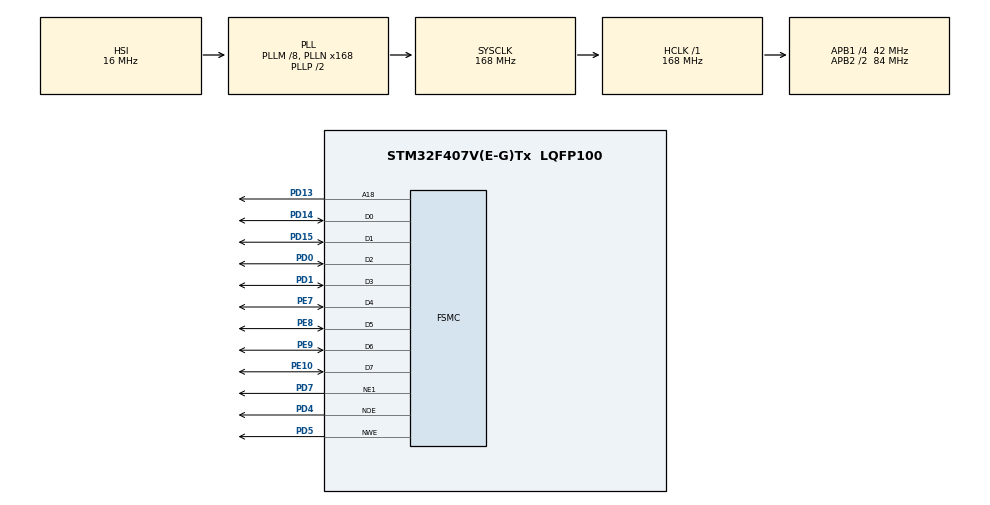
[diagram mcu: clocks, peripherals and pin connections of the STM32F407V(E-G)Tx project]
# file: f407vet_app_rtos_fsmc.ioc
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FREERTOS.Mutexes01=myLcdDma,Dynamic,NULL
FREERTOS.Tasks01=defaultTask,0,256,StartDefaultTask,As weak,NULL,Dynamic,NULL,NULL;myLopriority,-3,128,StartLopriority,As weak,NULL,Dynamic,NULL,NULL
FREERTOS.Timers01=myTimer01,cbTimer,osTimerPeriodic,As weak,NULL,Dynamic,NULL
FREERTOS.configUSE_TIMERS=1
FSMC.AddressSetupTime1=8
FSMC.BusTurnAroundDuration1=8
FSMC.DataSetupTime1=10
FSMC.ExtendedMode1=FSMC_EXTENDED_MODE_DISABLE
Mcu.Family=STM32F4
Mcu.Name=STM32F407V(E-G)Tx
Mcu.Package=LQFP100
NVIC.PriorityGroup=NVIC_PRIORITYGROUP_4
NVIC.TIM6_DAC_IRQn=true\:0\:0\:false\:false\:true\:false\:false
NVIC.TimeBase=TIM6_DAC_IRQn
NVIC.TimeBaseIP=TIM6
PA13.Mode=Trace_Asynchronous_SW
PA13.Signal=SYS_JTMS-SWDIO
PA14.Mode=Trace_Asynchronous_SW
PA14.Signal=SYS_JTCK-SWCLK
PB3.Mode=Trace_Asynchronous_SW
PB3.Signal=SYS_JTDO-SWO
PC14-OSC32_IN.Mode=LSE-External-Oscillator
PC14-OSC32_IN.Signal=RCC_OSC32_IN
PC15-OSC32_OUT.Mode=LSE-External-Oscillator
PC15-OSC32_OUT.Signal=RCC_OSC32_OUT
PD0.Mode=8b-d1
PD0.Signal=FSMC_D2
PD1.Mode=8b-d1
PD1.Signal=FSMC_D3
PD13.Mode=A18_1
PD13.Signal=FSMC_A18
PD14.Mode=8b-d1
PD14.Signal=FSMC_D0
PD15.Mode=8b-d1
PD15.Signal=FSMC_D1
PD4.Mode=Lcd1
PD4.Signal=FSMC_NOE
PD5.Mode=Lcd1
PD5.Signal=FSMC_NWE
PD7.Mode=NorPsramChipSelect1_1
PD7.Signal=FSMC_NE1
PE10.Mode=8b-d1
PE10.Signal=FSMC_D7
PE7.Mode=8b-d1
PE7.Signal=FSMC_D4
PE8.Mode=8b-d1
PE8.Signal=FSMC_D5
PE9.Mode=8b-d1
PE9.Signal=FSMC_D6
PH0-OSC_IN.Mode=HSE-External-Oscillator
PH0-OSC_IN.Signal=RCC_OSC_IN
PH1-OSC_OUT.Mode=HSE-External-Oscillator
PH1-OSC_OUT.Signal=RCC_OSC_OUT
ProjectManager.HeapSize=0x200
ProjectManager.StackSize=0x800
ProjectManager.TargetToolchain=TrueSTUDIO
RCC.48MHZClocksFreq_Value=84000000
RCC.AHBFreq_Value=168000000
RCC.APB1CLKDivider=RCC_HCLK_DIV4
RCC.APB1Freq_Value=42000000
RCC.APB1TimFreq_Value=84000000
RCC.APB2CLKDivider=RCC_HCLK_DIV2
RCC.APB2Freq_Value=84000000
RCC.APB2TimFreq_Value=168000000
RCC.CortexFreq_Value=168000000
RCC.HCLKFreq_Value=168000000
RCC.HSE_VALUE=8000000
RCC.HSI_VALUE=16000000
RCC.PLLM=8
RCC.PLLN=168
RCC.RCC_RTC_Clock_Source=RCC_RTCCLKSOURCE_LSE
RCC.RCC_RTC_Clock_SourceVirtual=RCC_RTCCLKSOURCE_LSE
RCC.SYSCLKFreq_VALUE=168000000
RCC.SYSCLKSource=RCC_SYSCLKSOURCE_PLLCLK
RCC.VCOOutputFreq_Value=336000000
VP_FREERTOS_VS_ENABLE.Mode=Enabled
VP_RTC_VS_RTC_Activate.Mode=RTC_Enabled
VP_SYS_VS_tim6.Mode=TIM6
board=custom

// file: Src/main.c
/**
  ******************************************************************************
  * @file           : main.c
  * @brief          : Main program body
  ******************************************************************************
  * This notice applies to any and all portions of this file
  * that are not between comment pairs USER CODE BEGIN and
  * USER CODE END. Other portions of this file, whether
  * inserted by the user or by software development tools
  * are owned by their respective copyright owners.
  *
  * Copyright (c) 2019 STMicroelectronics International N.V.
  * All rights reserved.
  *
  * Redistribution and use in source and binary forms, with or without
  * modification, are permitted, provided that the following conditions are met:
  *
  * 1. Redistribution of source code must retain the above copyright notice,
  *    this list of conditions and the following disclaimer.
  * 2. Redistributions in binary form must reproduce the above copyright notice,
  *    this list of conditions and the following disclaimer in the documentation
  *    and/or other materials provided with the distribution.
  * 3. Neither the name of STMicroelectronics nor the names of other
  *    contributors to this software may be used to endorse or promote products
  *    derived from this software without specific written permission.
  * 4. This software, including modifications and/or derivative works of this
  *    software, must execute solely and exclusively on microcontroller or
  *    microprocessor devices manufactured by or for STMicroelectronics.
  * 5. Redistribution and use of this software other than as permitted under
  *    this license is void and will automatically terminate your rights under
  *    this license.
  *
  * THIS SOFTWARE IS PROVIDED BY STMICROELECTRONICS AND CONTRIBUTORS "AS IS"
  * AND ANY EXPRESS, IMPLIED OR STATUTORY WARRANTIES, INCLUDING, BUT NOT
  * LIMITED TO, THE IMPLIED WARRANTIES OF MERCHANTABILITY, FITNESS FOR A
  * PARTICULAR PURPOSE AND NON-INFRINGEMENT OF THIRD PARTY INTELLECTUAL PROPERTY
  * RIGHTS ARE DISCLAIMED TO THE FULLEST EXTENT PERMITTED BY LAW. IN NO EVENT
  * SHALL STMICROELECTRONICS OR CONTRIBUTORS BE LIABLE FOR ANY DIRECT, INDIRECT,
  * INCIDENTAL, SPECIAL, EXEMPLARY, OR CONSEQUENTIAL DAMAGES (INCLUDING, BUT NOT
  * LIMITED TO, PROCUREMENT OF SUBSTITUTE GOODS OR SERVICES; LOSS OF USE, DATA,
  * OR PROFITS; OR BUSINESS INTERRUPTION) HOWEVER CAUSED AND ON ANY THEORY OF
  * LIABILITY, WHETHER IN CONTRACT, STRICT LIABILITY, OR TORT (INCLUDING
  * NEGLIGENCE OR OTHERWISE) ARISING IN ANY WAY OUT OF THE USE OF THIS SOFTWARE,
  * EVEN IF ADVISED OF THE POSSIBILITY OF SUCH DAMAGE.
  *
  ******************************************************************************
  */
#include "main.h"
#include "stm32f4xx_hal.h"
#include "cmsis_os.h"

RTC_HandleTypeDef hrtc;

SRAM_HandleTypeDef hsram1;

osThreadId defaultTaskHandle;
osThreadId myLopriorityHandle;
osTimerId myTimer01Handle;
osMutexId myLcdDmaHandle;

/* USER CODE BEGIN PV */
/* Private variables ---------------------------------------------------------*/

/* USER CODE END PV */

void SystemClock_Config(void);
static void MX_GPIO_Init(void);
static void MX_RTC_Init(void);
static void MX_FSMC_Init(void);
void StartDefaultTask(void const * argument);
void StartLopriority(void const * argument);
void cbTimer(void const * argument);

/* USER CODE BEGIN PFP */
/* Private function prototypes -----------------------------------------------*/

/* USER CODE END PFP */

int main(void)
{

  /* MCU Configuration----------------------------------------------------------*/

  /* Reset of all peripherals, Initializes the Flash interface and the Systick. */
  HAL_Init();

  /* Configure the system clock */
  SystemClock_Config();

  /* Initialize all configured peripherals */
  MX_GPIO_Init();
  MX_RTC_Init();
  MX_FSMC_Init();

  /* Create the mutex(es) */
  /* definition and creation of myLcdDma */
  osMutexDef(myLcdDma);
  myLcdDmaHandle = osMutexCreate(osMutex(myLcdDma));

  /* Create the timer(s) */
  /* definition and creation of myTimer01 */
  osTimerDef(myTimer01, cbTimer);
  myTimer01Handle = osTimerCreate(osTimer(myTimer01), osTimerPeriodic, NULL);

  /* USER CODE BEGIN RTOS_TIMERS */
  /* start timers, add new ones, ... */
  osTimerStart(myTimer01Handle, 250);
  /* USER CODE END RTOS_TIMERS */

  /* Create the thread(s) */
  /* definition and creation of defaultTask */
  osThreadDef(defaultTask, StartDefaultTask, osPriorityNormal, 0, 256);
  defaultTaskHandle = osThreadCreate(osThread(defaultTask), NULL);

  /* definition and creation of myLopriority */
  osThreadDef(myLopriority, StartLopriority, osPriorityIdle, 0, 128);
  myLopriorityHandle = osThreadCreate(osThread(myLopriority), NULL);

  /* Start scheduler */
  osKernelStart();

  /* We should never get here as control is now taken by the scheduler */

  /* Infinite loop */
  while (1)
  {

  }

}

void SystemClock_Config(void)
{

  RCC_OscInitTypeDef RCC_OscInitStruct;
  RCC_ClkInitTypeDef RCC_ClkInitStruct;
  RCC_PeriphCLKInitTypeDef PeriphClkInitStruct;

    /**Configure the main internal regulator output voltage
    */
  __HAL_RCC_PWR_CLK_ENABLE();

  __HAL_PWR_VOLTAGESCALING_CONFIG(PWR_REGULATOR_VOLTAGE_SCALE1);

    /**Initializes the CPU, AHB and APB busses clocks
    */
  RCC_OscInitStruct.OscillatorType = RCC_OSCILLATORTYPE_HSI|RCC_OSCILLATORTYPE_LSE;
  RCC_OscInitStruct.LSEState = RCC_LSE_ON;
  RCC_OscInitStruct.HSIState = RCC_HSI_ON;
  RCC_OscInitStruct.HSICalibrationValue = 16;
  RCC_OscInitStruct.PLL.PLLState = RCC_PLL_ON;
  RCC_OscInitStruct.PLL.PLLSource = RCC_PLLSOURCE_HSI;
  RCC_OscInitStruct.PLL.PLLM = 8;
  RCC_OscInitStruct.PLL.PLLN = 168;
  RCC_OscInitStruct.PLL.PLLP = RCC_PLLP_DIV2;
  RCC_OscInitStruct.PLL.PLLQ = 4;
  if (HAL_RCC_OscConfig(&RCC_OscInitStruct) != HAL_OK)
  {
    _Error_Handler(__FILE__, __LINE__);
  }

    /**Initializes the CPU, AHB and APB busses clocks
    */
  RCC_ClkInitStruct.ClockType = RCC_CLOCKTYPE_HCLK|RCC_CLOCKTYPE_SYSCLK
                              |RCC_CLOCKTYPE_PCLK1|RCC_CLOCKTYPE_PCLK2;
  RCC_ClkInitStruct.SYSCLKSource = RCC_SYSCLKSOURCE_PLLCLK;
  RCC_ClkInitStruct.AHBCLKDivider = RCC_SYSCLK_DIV1;
  RCC_ClkInitStruct.APB1CLKDivider = RCC_HCLK_DIV4;
  RCC_ClkInitStruct.APB2CLKDivider = RCC_HCLK_DIV2;

  if (HAL_RCC_ClockConfig(&RCC_ClkInitStruct, FLASH_LATENCY_5) != HAL_OK)
  {
    _Error_Handler(__FILE__, __LINE__);
  }

  PeriphClkInitStruct.PeriphClockSelection = RCC_PERIPHCLK_RTC;
  PeriphClkInitStruct.RTCClockSelection = RCC_RTCCLKSOURCE_LSE;
  if (HAL_RCCEx_PeriphCLKConfig(&PeriphClkInitStruct) != HAL_OK)
  {
    _Error_Handler(__FILE__, __LINE__);
  }

    /**Configure the Systick interrupt time
    */
  HAL_SYSTICK_Config(HAL_RCC_GetHCLKFreq()/1000);

    /**Configure the Systick
    */
  HAL_SYSTICK_CLKSourceConfig(SYSTICK_CLKSOURCE_HCLK);

  /* SysTick_IRQn interrupt configuration */
  HAL_NVIC_SetPriority(SysTick_IRQn, 15, 0);
}

/* RTC init function */
static void MX_RTC_Init(void)
{

    /**Initialize RTC Only
    */
  hrtc.Instance = RTC;
  hrtc.Init.HourFormat = RTC_HOURFORMAT_24;
  hrtc.Init.AsynchPrediv = 127;
  hrtc.Init.SynchPrediv = 255;
  hrtc.Init.OutPut = RTC_OUTPUT_DISABLE;
  hrtc.Init.OutPutPolarity = RTC_OUTPUT_POLARITY_HIGH;
  hrtc.Init.OutPutType = RTC_OUTPUT_TYPE_OPENDRAIN;
  if (HAL_RTC_Init(&hrtc) != HAL_OK)
  {
    _Error_Handler(__FILE__, __LINE__);
  }

}

/** Configure pins as
        * Analog
        * Input
        * Output
        * EVENT_OUT
        * EXTI
*/
static void MX_GPIO_Init(void)
{

  /* GPIO Ports Clock Enable */
  __HAL_RCC_GPIOC_CLK_ENABLE();
  __HAL_RCC_GPIOH_CLK_ENABLE();
  __HAL_RCC_GPIOE_CLK_ENABLE();
  __HAL_RCC_GPIOD_CLK_ENABLE();
  __HAL_RCC_GPIOA_CLK_ENABLE();
  __HAL_RCC_GPIOB_CLK_ENABLE();

}

/* FSMC initialization function */
static void MX_FSMC_Init(void)
{
  FSMC_NORSRAM_TimingTypeDef Timing;

  /** Perform the SRAM1 memory initialization sequence
  */
  hsram1.Instance = FSMC_NORSRAM_DEVICE;
  hsram1.Extended = FSMC_NORSRAM_EXTENDED_DEVICE;
  /* hsram1.Init */
  hsram1.Init.NSBank = FSMC_NORSRAM_BANK1;
  hsram1.Init.DataAddressMux = FSMC_DATA_ADDRESS_MUX_DISABLE;
  hsram1.Init.MemoryType = FSMC_MEMORY_TYPE_SRAM;
  hsram1.Init.MemoryDataWidth = FSMC_NORSRAM_MEM_BUS_WIDTH_8;
  hsram1.Init.BurstAccessMode = FSMC_BURST_ACCESS_MODE_DISABLE;
  hsram1.Init.WaitSignalPolarity = FSMC_WAIT_SIGNAL_POLARITY_LOW;
  hsram1.Init.WrapMode = FSMC_WRAP_MODE_DISABLE;
  hsram1.Init.WaitSignalActive = FSMC_WAIT_TIMING_BEFORE_WS;
  hsram1.Init.WriteOperation = FSMC_WRITE_OPERATION_ENABLE;
  hsram1.Init.WaitSignal = FSMC_WAIT_SIGNAL_DISABLE;
  hsram1.Init.ExtendedMode = FSMC_EXTENDED_MODE_DISABLE;
  hsram1.Init.AsynchronousWait = FSMC_ASYNCHRONOUS_WAIT_DISABLE;
  hsram1.Init.WriteBurst = FSMC_WRITE_BURST_DISABLE;
  hsram1.Init.PageSize = FSMC_PAGE_SIZE_NONE;
  /* Timing */
  Timing.AddressSetupTime = 5;
  Timing.AddressHoldTime = 15;
  Timing.DataSetupTime = 8;
  Timing.BusTurnAroundDuration = 1;
  Timing.CLKDivision = 16;
  Timing.DataLatency = 17;
  Timing.AccessMode = FSMC_ACCESS_MODE_A;
  /* ExtTiming */

  if (HAL_SRAM_Init(&hsram1, &Timing, NULL) != HAL_OK)
  {
    _Error_Handler(__FILE__, __LINE__);
  }

}

__weak void StartDefaultTask(void const * argument)
{

  for(;;)
  {
    osDelay(1);
  }
}

__weak void StartLopriority(void const * argument)
{
  for(;;)
  {
    osDelay(1);
  }
}

/* cbTimer function */
__weak void cbTimer(void const * argument)
{
}

void HAL_TIM_PeriodElapsedCallback(TIM_HandleTypeDef *htim)
{
  if (htim->Instance == TIM6) {
    HAL_IncTick();
  }
}

void _Error_Handler(char *file, int line)
{
  while(1)
  {
  }
}

/************************ (C) COPYRIGHT STMicroelectronics *****END OF FILE****/
